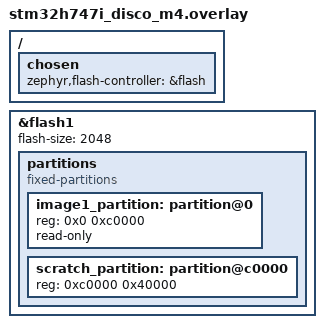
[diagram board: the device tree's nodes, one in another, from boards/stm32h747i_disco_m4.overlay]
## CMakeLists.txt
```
# SPDX-License-Identifier: Apache-2.0

cmake_minimum_required(VERSION 3.20.0)
find_package(Zephyr REQUIRED HINTS $ENV{ZEPHYR_BASE})
project(soc_flash_stm32h7)

FILE(GLOB app_sources src/*.c)
target_sources(app PRIVATE ${app_sources})
```

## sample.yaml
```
sample:
  name: SoC Flash on STM32H747
tests:
  sample.drivers.flash.st.stm32-nv-flash:
    platform_allow:
      - stm32h747i_disco_m7
      - stm32h747i_disco_m4
    integration_platforms:
      - stm32h747i_disco_m7
      - stm32h747i_disco_m4
    tags:
      - flash
      - stm32h747
```

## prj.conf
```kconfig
CONFIG_FLASH=y
CONFIG_FLASH_PAGE_LAYOUT=y
CONFIG_MPU_ALLOW_FLASH_WRITE=y
```

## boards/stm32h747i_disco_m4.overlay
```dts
/* SPDX-License-Identifier: Apache-2.0 */

/ {
	chosen {
		zephyr,flash-controller = &flash;
	};
};

&flash1 {
        flash-size = <2048>;
	partitions {
		compatible = "fixed-partitions";
			#address-cells = <0x1>;
			#size-cells = <0x1>;
			image1_partition: partition@0 {
				reg = <0x0 0xc0000>;
				read-only;
			};

		/* 256KiB scratch pad */
		scratch_partition: partition@c0000 {
			reg = <0xc0000 0x40000>;
		};
	};
};
```

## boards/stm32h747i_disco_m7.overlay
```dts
/* SPDX-License-Identifier: Apache-2.0 */

/delete-node/ &storage_partition;

/ {
	chosen {
		/delete-property/ zephyr,flash-controller;
		zephyr,flash-controller = &flash;
	};
};

&flash0 {
	compatible = "st,stm32-nv-flash", "soc-nv-flash";
	partitions {
		compatible = "fixed-partitions";
			#address-cells = <0x1>;
			#size-cells = <0x1>;
			image1_partition: partition@0 {
				reg = <0x0 0xc0000>;
				read-only;
			};

		/* 256KiB scratch pad */
		scratch_partition: partition@c0000 {
			reg = <0xc0000 0x40000>;
		};
	};
};
```

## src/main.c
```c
/*
 * Copyright (c) 2016 Linaro Limited
 *               2016 Intel Corporation
 *               2023 S&C Electric Company.
 *
 * SPDX-License-Identifier: Apache-2.0
 */

#include <zephyr/kernel.h>
#include <zephyr/drivers/flash.h>
#include <zephyr/storage/flash_map.h>
#include <zephyr/device.h>
#include <zephyr/devicetree.h>
#include <stdio.h>

#define TEST_PARTITION   scratch_partition
#define IMAGE1_PARTITION image1_partition

#define TEST_PARTITION_OFFSET FIXED_PARTITION_OFFSET(TEST_PARTITION)
#define TEST_PARTITION_DEVICE FIXED_PARTITION_DEVICE(TEST_PARTITION)
#define TEST_PARTITION_SIZE   FIXED_PARTITION_SIZE(TEST_PARTITION)

#define IMAGE1_PARTITION_OFFSET FIXED_PARTITION_OFFSET(IMAGE1_PARTITION)
#define IMAGE1_PARTITION_DEVICE FIXED_PARTITION_DEVICE(IMAGE1_PARTITION)
#define IMAGE1_PARTITION_SIZE   FIXED_PARTITION_SIZE(IMAGE1_PARTITION)

/* The write block size to use for read/write operation */
#define FLASH_WRITE_SIZE 32

int main(void)
{

	const struct device *flash_dev = TEST_PARTITION_DEVICE;
	uint32_t buffer[8];
	uint32_t buffer_1[8];
	uint32_t i, j, offset, blocks, count = 0;

	printf("\n   STM32H7 Flash API Sample Application\n");
	printf("   ========================================\n");
	printf("   Available partitions on SoC Flash\n");
	printf("   image1_partition        @%x, size %d\n", IMAGE1_PARTITION_OFFSET,
	       IMAGE1_PARTITION_SIZE);
	printf("   scratch_partition       @%x, size %d\n", TEST_PARTITION_OFFSET,
	       TEST_PARTITION_SIZE);

	if (!device_is_ready(flash_dev)) {
		printf("   Flash device not ready\n");
		return 0;
	}

	printf("\nFlash erase page at 0x%x, size %d\n", TEST_PARTITION_OFFSET, TEST_PARTITION_SIZE);
	if (flash_erase(flash_dev, TEST_PARTITION_OFFSET, TEST_PARTITION_SIZE) != 0) {
		printf("   Flash erase failed!\n");
	} else {
		printf("   Flash erase succeeded!\n");
	}

	printf("\nDoing Flash write/read operations\n");
	offset = TEST_PARTITION_OFFSET;
	blocks = TEST_PARTITION_SIZE / FLASH_WRITE_SIZE;
	/* STM32 flash supports 32byte program size. So block size is 32 */
	for (i = 0; i < FLASH_WRITE_SIZE / 4; i++) {
		if ((i % 4) == 0) {
			buffer[i] = 0xaa0055ff;
		} else if ((i % 4) == 1) {
			buffer[i] = 0x0055ff00;
		} else if ((i % 4) == 2) {
			buffer[i] = 0x55ff00aa;
		} else if ((i % 4) == 3) {
			buffer[i] = 0xff00aa55;
		}
	}

	for (i = 0; i < blocks; i++) {
		if (flash_write(flash_dev, offset + (i * FLASH_WRITE_SIZE), &buffer[0],
				sizeof(buffer)) != 0) {
			printf("   Flash write failed!\n");
			return 0;
		}
		if (i && ((i % 1024) == 0)) {
			printf("   Wrote %d blocks of 32 bytes\n", i);
		}
	}
	printf("   Wrote %d blocks of %d bytes\n", i, FLASH_WRITE_SIZE);

	for (j = 0; j < blocks; j++) {
		if (flash_read(flash_dev, offset + (j * FLASH_WRITE_SIZE), &buffer_1[0],
			       sizeof(buffer_1)) != 0) {
			printf("   Flash read failed!\n");
			return 0;
		}
		for (i = 0; i < FLASH_WRITE_SIZE / 4; i++) {
			if (buffer[i] != buffer_1[i]) {
				count++;
			}
		}
		if (j && ((j % 1024) == 0)) {
			printf("   read and verified up to 0x%x\n",
			       offset + (j * FLASH_WRITE_SIZE));
		}
	}
	if (count) {
		printf("   %d words read patterns wrong\n", count);
	} else {
		printf("   %d blocks read and verified correctly\n", blocks);
	}
	return 0;
}
```
